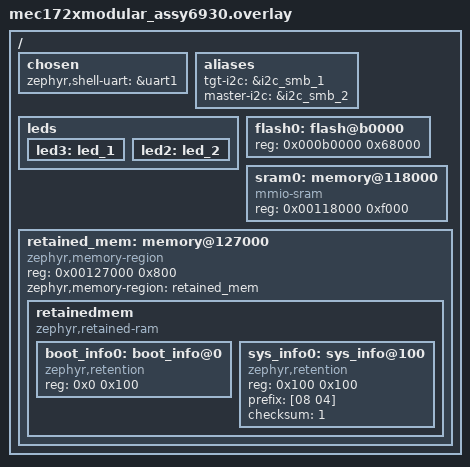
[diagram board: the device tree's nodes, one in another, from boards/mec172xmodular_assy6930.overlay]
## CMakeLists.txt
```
# SPDX-License-Identifier: Apache-2.0

cmake_minimum_required(VERSION 3.20.0)

find_package(Zephyr REQUIRED HINTS $ENV{ZEPHYR_BASE})
project(ram_retention)

target_sources(app PRIVATE src/main.c)
target_sources(app PRIVATE src/retained.c)
target_sources(app PRIVATE src/retention.c)
```

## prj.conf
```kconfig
# Driver

# console
CONFIG_CONSOLE=y
CONFIG_UART_CONSOLE=y
CONFIG_LOG=y

#SHELL
CONFIG_SHELL=y
CONFIG_GPIO_SHELL=y
CONFIG_SHELL_PROMPT_UART="MCHP:~$ "

# RETENTION
CONFIG_RETAINED_MEM=y
CONFIG_RETENTION=y

CONFIG_REBOOT=y
```

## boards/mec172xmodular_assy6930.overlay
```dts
/*
 * Copyright (c) 2020 Intel Corporation
 *
 * SPDX-License-Identifier: Apache-2.0
 */


/ {
	chosen {
		zephyr,shell-uart = &uart1;
	};

	aliases {
        tgt-i2c = &i2c_smb_1;
        master-i2c = &i2c_smb_2;
    };

	leds {
		led3: led_1 {
			status = "okay";
		};
		led2: led_2 {
			status = "okay";
		};
	};

	/delete-node/ flash@c0000;
	/delete-node/ memory@118000;
	flash0: flash@b0000 {
		reg = <0x000b0000 0x68000>;
	};

	sram0: memory@118000 {
		compatible = "mmio-sram";
		// reg = <0x00118000 0xf800>;
		reg = <0x00118000 0xf000>;
	};

	retained_mem: memory@127000 {
		compatible = "zephyr,memory-region", "mmio-sram";
		reg = <0x00127000 0x800>; /* 起始位址與大小 */
		zephyr,memory-region = "retained_mem";
		status = "okay";

		retainedmem {
			compatible = "zephyr,retained-ram";
			status = "okay";
			#address-cells = <1>;
			#size-cells = <1>;

			boot_info0: boot_info@0 {
				compatible = "zephyr,retention";
				status = "okay";
				reg = <0x0 0x100>;
			};

			sys_info0: sys_info@100 {
				compatible = "zephyr,retention";
				status = "okay";
				reg = <0x100 0x100>;

				prefix = [08 04];
				checksum = <1>;
			};
		};
	};
};
```

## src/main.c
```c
/*
 * Copyright (c) 2012-2014 Wind River Systems, Inc.
 *
 * SPDX-License-Identifier: Apache-2.0
 */

#include <stdio.h>

#include <zephyr/logging/log.h>

LOG_MODULE_REGISTER(main, LOG_LEVEL_INF);

int main(void)
{
	LOG_INF("Hello World! %s", CONFIG_BOARD_TARGET);

	return 0;
}
```

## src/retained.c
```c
#include <zephyr/kernel.h>
#include <zephyr/device.h>
#include <zephyr/devicetree.h>
#include <zephyr/drivers/retained_mem.h>
#include <zephyr/retention/retention.h>
#include <zephyr/logging/log.h>

LOG_MODULE_REGISTER(app_retained, LOG_LEVEL_INF);

#define RETENTION_MAGIC 0xABCDABCD

/* 1. 從 Devicetree 取得我們定義的 boot_info0 裝置實例 */
static const struct device *retain_dev = DEVICE_DT_GET(DT_NODELABEL(boot_info0));

/* 2. 定義您要儲存的自訂資料結構（注意：大小不可超過 DTS 規定的 0x100 空間） */
struct my_boot_data {
    uint32_t magic;
    uint32_t reset_count;
    uint8_t  boot_mode;
    char     magic_str[8];
};

#include <zephyr/init.h>

static int init_config(void)
{
    int ret;
    struct my_boot_data data;

    LOG_INF("--- Zephyr Retention system test ---");

    /* 檢查裝置是否已經就緒 */
    if (!device_is_ready(retain_dev)) {
        LOG_ERR("Retention device is not ready!");
        return -1;
    }

    /* 3. 讀取保留記憶體中的資料 */
    /* 參數：(裝置, 記憶體偏移量, 緩衝區指標, 讀取長度) */
    ret = retention_read(retain_dev, 0, (uint8_t *)&data, sizeof(data));

    if (ret == -EILSEQ || ret == -ENOMSG || data.magic != RETENTION_MAGIC) {
        /* 
         * 當系統第一次冷開機（Cold Boot），或者不正常斷電導致資料損毀時，
         * Prefix 或 Checksum 會驗證失敗，retention_read 會回傳 -EILSEQ 或 -ENOMSG。
         * 此時必須將區域初始化（或清空）。
         */
        LOG_WRN("Invalid retention data detected (possibly first boot), initializing...");

        /* 初始化結構體資料 */
        data.reset_count = 1;
        data.boot_mode = 0x01;
        data.magic = RETENTION_MAGIC;
        snprintk(data.magic_str, sizeof(data.magic_str), "APP");

        /* 第一次寫入前，強烈建議先呼叫 retention_clear 清空，這會重置校驗狀態 */
        ret = retention_clear(retain_dev);
        if (ret < 0) {
            LOG_ERR("Failed to clear Retention: %d", ret);
            return ret;
        }

        /* 寫入初始資料 */
        ret = retention_write(retain_dev, 0, (uint8_t *)&data, sizeof(data));
        if (ret < 0) {
            LOG_ERR("Failed to write Retention: %d", ret);
            return ret;
        }
        LOG_INF("Initialization written successfully!");

    } else if (ret < 0) {
        /* 其他硬體或驅動錯誤 */
        LOG_ERR("Failed to read Retention, error code: %d", ret);
    } else {
        /* 
         * 讀取成功！代表這是熱重啟（Warm Boot，如軟體重啟或看門狗重啟），
         * 資料成功被保留下來了。
         */
        LOG_INF("Successfully read retention data!");
        LOG_INF("Current reset count (Reset Count): %d", data.reset_count);
        LOG_INF("Boot mode (Boot Mode): 0x%02X", data.boot_mode);
        LOG_INF("Magic string: %s", data.magic_str);

        /* 遞增計數器，並寫回記憶體，供下次重啟使用 */
        data.reset_count++;
        ret = retention_write(retain_dev, 0, (uint8_t *)&data, sizeof(data));
        if (ret < 0) {
            LOG_ERR("Failed to update Retention data: %d", ret);
        }
    }

    return 0;
}

SYS_INIT(init_config, APPLICATION, 0);
```

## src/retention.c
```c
#include <zephyr/kernel.h>
#include <zephyr/device.h>
#include <zephyr/devicetree.h>
#include <zephyr/retention/retention.h>
#include <zephyr/logging/log.h>

LOG_MODULE_REGISTER(app_retention, LOG_LEVEL_INF);

/* 1. 從 Devicetree 取得我們定義的 sys_info0 裝置實例 */
static const struct device *retention_dev = DEVICE_DT_GET(DT_NODELABEL(sys_info0));

/* 2. 定義您要儲存的自訂資料結構（注意：大小不可超過 DTS 規定的 0x100 空間） */
struct boot_state {
    uint32_t count;
    uint32_t mode;
};

#include <zephyr/init.h>

static int init_config(void)
{
    struct boot_state state;
    int ret;

    if (!device_is_ready(retention_dev)) {
        LOG_ERR("Retention device not ready");
        return -EINVAL;
    }

    /* 🟢 步驟 1：使用 retention_is_valid 檢查魔術字串(prefix)與校驗和(checksum) */
    if (retention_is_valid(retention_dev) == 1) {
        
        /* 🟢 步驟 2：資料有效，直接讀取 */
        ret = retention_read(retention_dev, 0, (uint8_t *)&state, sizeof(state));
        if (ret == 0) {
            LOG_INF("Success! Read retention data successfully! Count: %d, Mode: 0x%08x", state.count, state.mode);
            state.count++;
        }
    } else {
        /* 🔴 步驟 3：資料無效（如首次冷開機），進行初始化 */
        LOG_WRN("Retention data is invalid, initializing...");
        state.count = 1;
        state.mode = 0xAABBCCDD;
        
        /* 注意：寫入前不需要手動 clear，底下的 write 會自動覆蓋並重新計算校驗 */
    }

    /* 🟢 步驟 4：將最新狀態寫回保留區（驅動會自動更新內部的 prefix 與 checksum） */
    ret = retention_write(retention_dev, 0, (uint8_t *)&state, sizeof(state));
    if (ret < 0) {
        LOG_ERR("寫入失敗: %d", ret);
    }

    return 0;
}

SYS_INIT(init_config, APPLICATION, 0);
```
